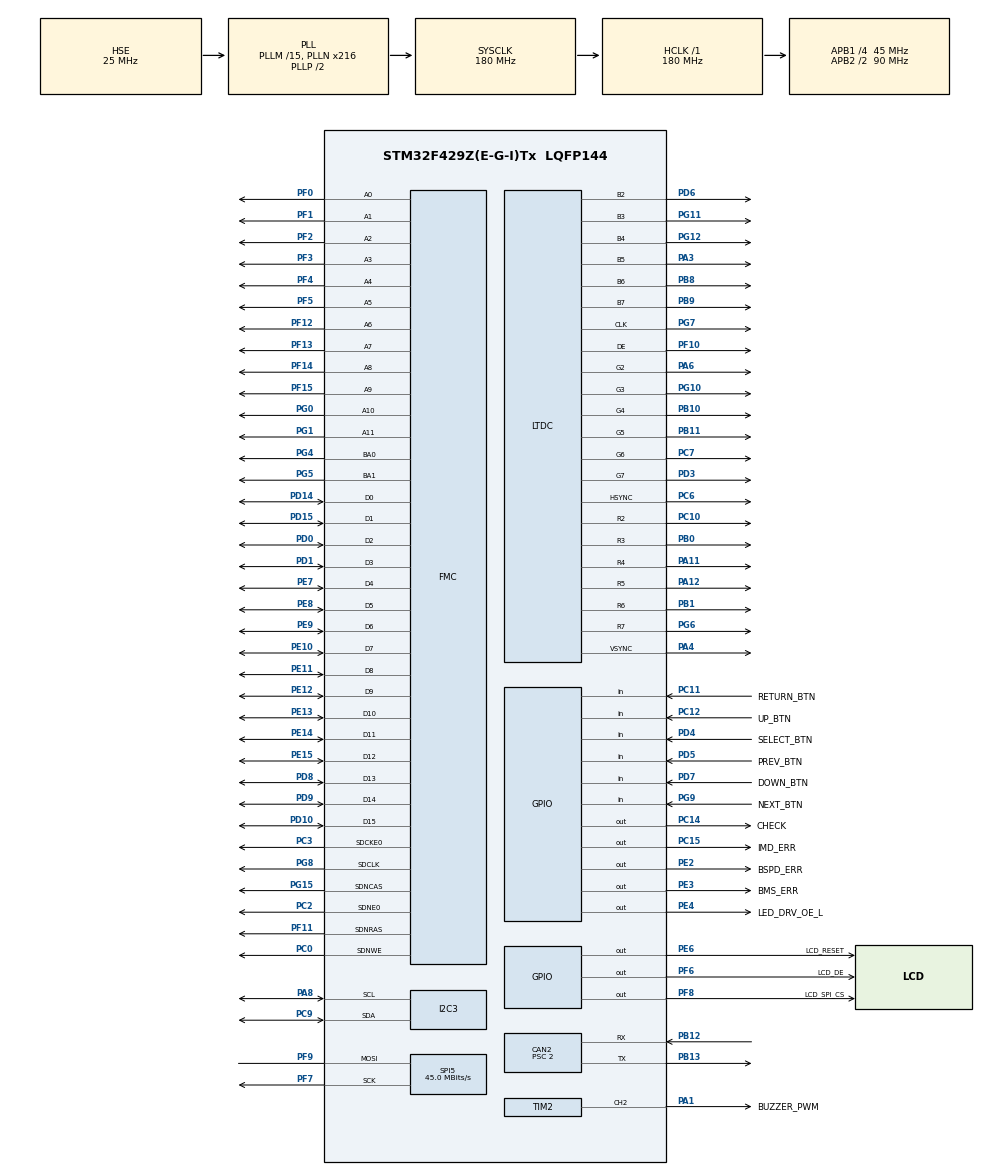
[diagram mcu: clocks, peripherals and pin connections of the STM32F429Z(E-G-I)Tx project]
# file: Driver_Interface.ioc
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CAN2.BS1=CAN_BS1_13TQ
CAN2.BS2=CAN_BS2_2TQ
CAN2.CalculateTimeBit=711
CAN2.CalculateTimeQuantum=44.44444444444444
CAN2.Prescaler=2
FREERTOS.Tasks01=defaultTask,0,128,StartDefaultTask,Default
Mcu.Family=STM32F4
Mcu.Name=STM32F429Z(E-G-I)Tx
Mcu.Package=LQFP144
NVIC.CAN2_RX0_IRQn=true\:5\:0\:false
NVIC.PriorityGroup=NVIC_PRIORITYGROUP_4
NVIC.TIM1_UP_TIM10_IRQn=true\:0\:0\:false
NVIC.TimeBase=TIM1_UP_TIM10_IRQn
NVIC.TimeBaseIP=TIM1
PA1.GPIO_Label=BUZZER_PWM
PA1.Signal=S_TIM2_CH2
PA11.Mode=RGB666
PA11.Signal=LTDC_R4
PA12.Mode=RGB666
PA12.Signal=LTDC_R5
PA13.Mode=Trace-Asynchronous_SW
PA13.Signal=SYS_JTMS-SWDIO
PA14.Mode=Trace-Asynchronous_SW
PA14.Signal=SYS_JTCK-SWCLK
PA3.Mode=RGB666
PA3.Signal=LTDC_B5
PA4.Mode=RGB666
PA4.Signal=LTDC_VSYNC
PA6.Mode=RGB666
PA6.Signal=LTDC_G2
PA8.Mode=I2C
PA8.Signal=I2C3_SCL
PB0.Mode=RGB666
PB0.Signal=LTDC_R3
PB1.Mode=RGB666
PB1.Signal=LTDC_R6
PB10.Mode=RGB666
PB10.Signal=LTDC_G4
PB11.Mode=RGB666
PB11.Signal=LTDC_G5
PB12.Mode=Slave
PB12.Signal=CAN2_RX
PB13.Mode=Slave
PB13.Signal=CAN2_TX
PB3.Mode=Trace-Asynchronous_SW
PB3.Signal=SYS_JTDO-SWO
PB8.Mode=RGB666
PB8.Signal=LTDC_B6
PB9.Mode=RGB666
PB9.Signal=LTDC_B7
PC0.Signal=FMC_SDNWE
PC10.Mode=RGB666
PC10.Signal=LTDC_R2
PC11.GPIO_Label=RETURN_BTN
PC11.Signal=GPIO_Input
PC12.GPIO_Label=UP_BTN
PC12.Signal=GPIO_Input
PC14/OSC32_IN.GPIO_Label=CHECK
PC14/OSC32_IN.Signal=GPIO_Output
PC15/OSC32_OUT.GPIO_Label=IMD_ERR
PC15/OSC32_OUT.Signal=GPIO_Output
PC2.Mode=SdramChipSelect1_1
PC2.Signal=FMC_SDNE0
PC3.Mode=SdramChipSelect1_1
PC3.Signal=FMC_SDCKE0
PC6.Mode=RGB666
PC6.Signal=LTDC_HSYNC
PC7.Mode=RGB666
PC7.Signal=LTDC_G6
PC9.Mode=I2C
PC9.Signal=I2C3_SDA
PD0.Signal=FMC_D2_DA2
PD1.Signal=FMC_D3_DA3
PD10.Signal=FMC_D15_DA15
PD14.Signal=FMC_D0_DA0
PD15.Signal=FMC_D1_DA1
PD3.Mode=RGB666
PD3.Signal=LTDC_G7
PD4.GPIO_Label=SELECT_BTN
PD4.Signal=GPIO_Input
PD5.GPIO_Label=PREV_BTN
PD5.Signal=GPIO_Input
PD6.Mode=RGB666
PD6.Signal=LTDC_B2
PD7.GPIO_Label=DOWN_BTN
PD7.Signal=GPIO_Input
PD8.Signal=FMC_D13_DA13
PD9.Signal=FMC_D14_DA14
PE10.Signal=FMC_D7_DA7
PE11.Signal=FMC_D8_DA8
PE12.Signal=FMC_D9_DA9
PE13.Signal=FMC_D10_DA10
PE14.Signal=FMC_D11_DA11
PE15.Signal=FMC_D12_DA12
PE2.GPIO_Label=BSPD_ERR
PE2.Signal=GPIO_Output
PE3.GPIO_Label=BMS_ERR
PE3.Signal=GPIO_Output
PE4.GPIO_Label=LED_DRV_OE_L
PE4.Signal=GPIO_Output
PE6.GPIO_Label=LCD_RESET
PE6.Signal=GPIO_Output
PE7.Signal=FMC_D4_DA4
PE8.Signal=FMC_D5_DA5
PE9.Signal=FMC_D6_DA6
PF0.Signal=FMC_A0
PF1.Signal=FMC_A1
PF10.Mode=RGB666
PF10.Signal=LTDC_DE
PF11.Signal=FMC_SDNRAS
PF12.Signal=FMC_A6
PF13.Signal=FMC_A7
PF14.Signal=FMC_A8
PF15.Signal=FMC_A9
PF2.Signal=FMC_A2
PF3.Signal=FMC_A3
PF4.Signal=FMC_A4
PF5.Signal=FMC_A5
PF6.GPIO_Label=LCD_DE
PF6.Signal=GPIO_Output
PF7.Mode=Simplex_Bidirectional_Master
PF7.Signal=SPI5_SCK
PF8.GPIO_Label=LCD_SPI_CS
PF8.Signal=GPIO_Output
PF9.Mode=Simplex_Bidirectional_Master
PF9.Signal=SPI5_MOSI
PG0.Signal=FMC_A10
PG1.Signal=FMC_A11
PG10.Mode=RGB666
PG10.Signal=LTDC_G3
PG11.Mode=RGB666
PG11.Signal=LTDC_B3
PG12.Mode=RGB666
PG12.Signal=LTDC_B4
PG15.Signal=FMC_SDNCAS
PG4.Signal=FMC_A14_BA0
PG5.Signal=FMC_A15_BA1
PG6.Mode=RGB666
PG6.Signal=LTDC_R7
PG7.Mode=RGB666
PG7.Signal=LTDC_CLK
PG8.Signal=FMC_SDCLK
PG9.GPIO_Label=NEXT_BTN
PG9.Signal=GPIO_Input
PH0/OSC_IN.Mode=HSE-External-Oscillator
PH0/OSC_IN.Signal=RCC_OSC_IN
PH1/OSC_OUT.Mode=HSE-External-Oscillator
PH1/OSC_OUT.Signal=RCC_OSC_OUT
ProjectManager.HeapSize=0x400
ProjectManager.StackSize=0x200
ProjectManager.TargetToolchain=SW4STM32
RCC.48MHZClocksFreq_Value=90000000
RCC.AHBFreq_Value=180000000
RCC.APB1CLKDivider=RCC_HCLK_DIV4
RCC.APB1Freq_Value=45000000
RCC.APB1TimCLKDivider=1
RCC.APB1TimFreq_Value=45000000
RCC.APB2CLKDivider=RCC_HCLK_DIV2
RCC.APB2Freq_Value=90000000
RCC.APB2TimCLKDivider=1
RCC.APB2TimFreq_Value=90000000
RCC.CortexFreq_Value=180000000
RCC.HCLKFreq_Value=180000000
RCC.HSE_VALUE=25000000
RCC.HSI_VALUE=16000000
RCC.LSE_VALUE=32768
RCC.PLLM=15
RCC.PLLN=216
RCC.PLLSAIDivR=RCC_PLLSAIDIVR_4
RCC.PLLSAIN=72
RCC.PLLSAIR=5
RCC.PLLSourceVirtual=RCC_PLLSOURCE_HSE
RCC.SYSCLKFreq_VALUE=180000000
RCC.SYSCLKSource=RCC_SYSCLKSOURCE_PLLCLK
RCC.VCOOutputFreq_Value=360000000
SH.FMC_A0.0=FMC_A0,12b-sda1
SH.FMC_A1.0=FMC_A1,12b-sda1
SH.FMC_A10.0=FMC_A10,12b-sda1
SH.FMC_A11.0=FMC_A11,12b-sda1
SH.FMC_A14_BA0.0=FMC_BA0,FourSdramBanks1
SH.FMC_A15_BA1.0=FMC_BA1,FourSdramBanks1
SH.FMC_A2.0=FMC_A2,12b-sda1
SH.FMC_A3.0=FMC_A3,12b-sda1
SH.FMC_A4.0=FMC_A4,12b-sda1
SH.FMC_A5.0=FMC_A5,12b-sda1
SH.FMC_A6.0=FMC_A6,12b-sda1
SH.FMC_A7.0=FMC_A7,12b-sda1
SH.FMC_A8.0=FMC_A8,12b-sda1
SH.FMC_A9.0=FMC_A9,12b-sda1
SH.FMC_D0_DA0.0=FMC_D0,sd-16b-d1
SH.FMC_D10_DA10.0=FMC_D10,sd-16b-d1
SH.FMC_D11_DA11.0=FMC_D11,sd-16b-d1
SH.FMC_D12_DA12.0=FMC_D12,sd-16b-d1
SH.FMC_D13_DA13.0=FMC_D13,sd-16b-d1
SH.FMC_D14_DA14.0=FMC_D14,sd-16b-d1
SH.FMC_D15_DA15.0=FMC_D15,sd-16b-d1
SH.FMC_D1_DA1.0=FMC_D1,sd-16b-d1
SH.FMC_D2_DA2.0=FMC_D2,sd-16b-d1
SH.FMC_D3_DA3.0=FMC_D3,sd-16b-d1
SH.FMC_D4_DA4.0=FMC_D4,sd-16b-d1
SH.FMC_D5_DA5.0=FMC_D5,sd-16b-d1
SH.FMC_D6_DA6.0=FMC_D6,sd-16b-d1
SH.FMC_D7_DA7.0=FMC_D7,sd-16b-d1
SH.FMC_D8_DA8.0=FMC_D8,sd-16b-d1
SH.FMC_D9_DA9.0=FMC_D9,sd-16b-d1
SH.FMC_SDCLK.0=FMC_SDCLK,12b-sda1
SH.FMC_SDNCAS.0=FMC_SDNCAS,12b-sda1
SH.FMC_SDNRAS.0=FMC_SDNRAS,12b-sda1
SH.FMC_SDNWE.0=FMC_SDNWE,12b-sda1
SH.S_TIM2_CH2.0=TIM2_CH2,PWM Generation2 CH2
SPI5.BaudRatePrescaler=SPI_BAUDRATEPRESCALER_2
SPI5.CalculateBaudRate=45.0 MBits/s
SPI5.Direction=SPI_DIRECTION_1LINE
SPI5.Mode=SPI_MODE_MASTER
TIM2.Channel-PWM\ Generation2\ CH2=TIM_CHANNEL_2
VP_DMA2D_VS_DMA2D.Mode=DMA2D_Activate
VP_FREERTOS_VS_ENABLE.Mode=Enabled
VP_SYS_VS_tim1.Mode=TIM1
board=Driver_Interface

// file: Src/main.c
/**
  ******************************************************************************
  * File Name          : main.c
  * Description        : Main program body
  ******************************************************************************
  *
  * COPYRIGHT(c) 2016 STMicroelectronics
  *
  * Redistribution and use in source and binary forms, with or without modification,
  * are permitted provided that the following conditions are met:
  *   1. Redistributions of source code must retain the above copyright notice,
  *      this list of conditions and the following disclaimer.
  *   2. Redistributions in binary form must reproduce the above copyright notice,
  *      this list of conditions and the following disclaimer in the documentation
  *      and/or other materials provided with the distribution.
  *   3. Neither the name of STMicroelectronics nor the names of its contributors
  *      may be used to endorse or promote products derived from this software
  *      without specific prior written permission.
  *
  * THIS SOFTWARE IS PROVIDED BY THE COPYRIGHT HOLDERS AND CONTRIBUTORS "AS IS"
  * AND ANY EXPRESS OR IMPLIED WARRANTIES, INCLUDING, BUT NOT LIMITED TO, THE
  * IMPLIED WARRANTIES OF MERCHANTABILITY AND FITNESS FOR A PARTICULAR PURPOSE ARE
  * DISCLAIMED. IN NO EVENT SHALL THE COPYRIGHT HOLDER OR CONTRIBUTORS BE LIABLE
  * FOR ANY DIRECT, INDIRECT, INCIDENTAL, SPECIAL, EXEMPLARY, OR CONSEQUENTIAL
  * DAMAGES (INCLUDING, BUT NOT LIMITED TO, PROCUREMENT OF SUBSTITUTE GOODS OR
  * SERVICES; LOSS OF USE, DATA, OR PROFITS; OR BUSINESS INTERRUPTION) HOWEVER
  * CAUSED AND ON ANY THEORY OF LIABILITY, WHETHER IN CONTRACT, STRICT LIABILITY,
  * OR TORT (INCLUDING NEGLIGENCE OR OTHERWISE) ARISING IN ANY WAY OUT OF THE USE
  * OF THIS SOFTWARE, EVEN IF ADVISED OF THE POSSIBILITY OF SUCH DAMAGE.
  *
  ******************************************************************************
  */
#include "stm32f4xx_hal.h"
#include "cmsis_os.h"

/* USER CODE BEGIN Includes */

#include "led.h"
#include "can.h"
#include "buttons.h"
#include "GUI.h"

#include "lcd_spi.h"
#include "ili9341.h"

/* USER CODE END Includes */

CAN_HandleTypeDef hcan2;

DMA2D_HandleTypeDef hdma2d;

I2C_HandleTypeDef hi2c3;

LTDC_HandleTypeDef hltdc;

SPI_HandleTypeDef hspi5;

TIM_HandleTypeDef htim2;

SDRAM_HandleTypeDef hsdram1;
osThreadId defaultTaskHandle;

/* USER CODE BEGIN PV */
CAN_HandleTypeDef hcan1;
/* Private variables ---------------------------------------------------------*/
osThreadId buttonTaskHandle;
osThreadId ledTaskHandle;
osThreadId canTaskHandle;
osMessageQId stateButtonQueue;
osMessageQId interfaceButtonQueue;

/* USER CODE END PV */

void SystemClock_Config(void);
static void MX_GPIO_Init(void);
static void MX_CAN2_Init(void);
static void MX_DMA2D_Init(void);
static void MX_FMC_Init(void);
static void MX_LTDC_Init(void);
static void MX_SPI5_Init(void);
static void MX_TIM2_Init(void);
static void MX_I2C3_Init(void);
void StartDefaultTask(void const * argument);

void HAL_TIM_MspPostInit(TIM_HandleTypeDef *htim);

/* USER CODE BEGIN PFP */
/* Private function prototypes -----------------------------------------------*/
/* USER CODE END PFP */

int main(void)
{

  /* MCU Configuration----------------------------------------------------------*/

  /* Reset of all peripherals, Initializes the Flash interface and the Systick. */
  HAL_Init();

  /* Configure the system clock */
  SystemClock_Config();

  /* Initialize all configured peripherals */
  MX_GPIO_Init();
  MX_CAN2_Init();
  MX_DMA2D_Init();
  MX_FMC_Init();
  MX_LTDC_Init();
  MX_SPI5_Init();
  MX_TIM2_Init();
  MX_I2C3_Init();

  /* USER CODE BEGIN 2 */
  UserInitCan2();
  HAL_GPIO_WritePin(CHECK_GPIO_Port, CHECK_Pin, GPIO_PIN_RESET);
  HAL_GPIO_WritePin(CHECK_GPIO_Port, CHECK_Pin, GPIO_PIN_SET);

//  HAL_GPIO_WritePin(BMS_ERR_GPIO_Port, BMS_ERR_Pin, GPIO_PIN_RESET);
//  HAL_GPIO_WritePin(BMS_ERR_GPIO_Port, BMS_ERR_Pin, GPIO_PIN_SET);

//  char recv_string[10] = "";
//  HAL_SDRAM_Write_8b(&hsdram1, 0, "hi", 3);
//  HAL_SDRAM_Read_8b(&hsdram1, 0, recv_string, 3);

  /* USER CODE END 2 */

  /* Create the thread(s) */
  /* definition and creation of defaultTask */
  osThreadDef(defaultTask, StartDefaultTask, osPriorityNormal, 0, 128);
  defaultTaskHandle = osThreadCreate(osThread(defaultTask), NULL);

  /* USER CODE BEGIN RTOS_THREADS */
  	  /* Button polling task. 100Hz. */
	  osThreadDef(buttonTask, vPollButtonsTask, osPriorityAboveNormal, 1, 500);
	  buttonTaskHandle = osThreadCreate(osThread(buttonTask), NULL);

	  osThreadDef(ledTask, vLedUpdateTask, osPriorityHigh, 1, 1024);
	  ledTaskHandle = osThreadCreate(osThread(ledTask), NULL);

	  osThreadDef(canTask, vCanTask, osPriorityAboveNormal, 1, 500);
	  canTaskHandle = osThreadCreate(osThread(canTask), NULL);

  /* USER CODE END RTOS_THREADS */

  /* USER CODE BEGIN RTOS_QUEUES */
	  osMessageQDef(ibutton_queue, 12, ButtonObject); // Declare a message queue
	  interfaceButtonQueue = osMessageCreate(osMessageQ(ibutton_queue), NULL);

	  osMessageQDef(sbutton_queue, 12, ButtonObject); // Declare a message queue
	  stateButtonQueue = osMessageCreate(osMessageQ(sbutton_queue), NULL);

  /* USER CODE END RTOS_QUEUES */

  /* Start scheduler */
  osKernelStart();

  /* We should never get here as control is now taken by the scheduler */

  /* Infinite loop */
  while (1)
  {

  }

}

/** System Clock Configuration
*/
void SystemClock_Config(void)
{

  RCC_OscInitTypeDef RCC_OscInitStruct;
  RCC_ClkInitTypeDef RCC_ClkInitStruct;
  RCC_PeriphCLKInitTypeDef PeriphClkInitStruct;

  __PWR_CLK_ENABLE();

  __HAL_PWR_VOLTAGESCALING_CONFIG(PWR_REGULATOR_VOLTAGE_SCALE1);

  RCC_OscInitStruct.OscillatorType = RCC_OSCILLATORTYPE_HSE;
  RCC_OscInitStruct.HSEState = RCC_HSE_ON;
  RCC_OscInitStruct.PLL.PLLState = RCC_PLL_ON;
  RCC_OscInitStruct.PLL.PLLSource = RCC_PLLSOURCE_HSE;
  RCC_OscInitStruct.PLL.PLLM = 15;
  RCC_OscInitStruct.PLL.PLLN = 216;
  RCC_OscInitStruct.PLL.PLLP = RCC_PLLP_DIV2;
  RCC_OscInitStruct.PLL.PLLQ = 4;
  HAL_RCC_OscConfig(&RCC_OscInitStruct);

  HAL_PWREx_ActivateOverDrive();

  RCC_ClkInitStruct.ClockType = RCC_CLOCKTYPE_HCLK|RCC_CLOCKTYPE_SYSCLK
                              |RCC_CLOCKTYPE_PCLK1|RCC_CLOCKTYPE_PCLK2;
  RCC_ClkInitStruct.SYSCLKSource = RCC_SYSCLKSOURCE_PLLCLK;
  RCC_ClkInitStruct.AHBCLKDivider = RCC_SYSCLK_DIV1;
  RCC_ClkInitStruct.APB1CLKDivider = RCC_HCLK_DIV4;
  RCC_ClkInitStruct.APB2CLKDivider = RCC_HCLK_DIV2;
  HAL_RCC_ClockConfig(&RCC_ClkInitStruct, FLASH_LATENCY_5);

  PeriphClkInitStruct.PeriphClockSelection = RCC_PERIPHCLK_LTDC;
  PeriphClkInitStruct.PLLSAI.PLLSAIN = 72;
  PeriphClkInitStruct.PLLSAI.PLLSAIR = 5;
  PeriphClkInitStruct.PLLSAIDivR = RCC_PLLSAIDIVR_4;
  HAL_RCCEx_PeriphCLKConfig(&PeriphClkInitStruct);

  HAL_SYSTICK_Config(HAL_RCC_GetHCLKFreq()/1000);

  HAL_SYSTICK_CLKSourceConfig(SYSTICK_CLKSOURCE_HCLK);

  /* SysTick_IRQn interrupt configuration */
  HAL_NVIC_SetPriority(SysTick_IRQn, 15, 0);
}

/* CAN2 init function */
void MX_CAN2_Init(void)
{

  hcan2.Instance = CAN2;
  hcan2.Init.Prescaler = 2;
  hcan2.Init.Mode = CAN_MODE_NORMAL;
  hcan2.Init.SJW = CAN_SJW_1TQ;
  hcan2.Init.BS1 = CAN_BS1_13TQ;
  hcan2.Init.BS2 = CAN_BS2_2TQ;
  hcan2.Init.TTCM = DISABLE;
  hcan2.Init.ABOM = DISABLE;
  hcan2.Init.AWUM = DISABLE;
  hcan2.Init.NART = DISABLE;
  hcan2.Init.RFLM = DISABLE;
  hcan2.Init.TXFP = DISABLE;
  HAL_CAN_Init(&hcan2);

}

/* DMA2D init function */
void MX_DMA2D_Init(void)
{

  hdma2d.Instance = DMA2D;
  hdma2d.Init.Mode = DMA2D_M2M;
  hdma2d.Init.ColorMode = DMA2D_ARGB8888;
  hdma2d.Init.OutputOffset = 0;
  hdma2d.LayerCfg[1].InputOffset = 0;
  hdma2d.LayerCfg[1].InputColorMode = CM_ARGB8888;
  hdma2d.LayerCfg[1].AlphaMode = DMA2D_NO_MODIF_ALPHA;
  hdma2d.LayerCfg[1].InputAlpha = 0;
  HAL_DMA2D_Init(&hdma2d);

  HAL_DMA2D_ConfigLayer(&hdma2d, 1);

}

/* I2C3 init function */
void MX_I2C3_Init(void)
{

  hi2c3.Instance = I2C3;
  hi2c3.Init.ClockSpeed = 100000;
  hi2c3.Init.DutyCycle = I2C_DUTYCYCLE_2;
  hi2c3.Init.OwnAddress1 = 0;
  hi2c3.Init.AddressingMode = I2C_ADDRESSINGMODE_7BIT;
  hi2c3.Init.DualAddressMode = I2C_DUALADDRESS_DISABLED;
  hi2c3.Init.OwnAddress2 = 0;
  hi2c3.Init.GeneralCallMode = I2C_GENERALCALL_DISABLED;
  hi2c3.Init.NoStretchMode = I2C_NOSTRETCH_DISABLED;
  HAL_I2C_Init(&hi2c3);

}

/* LTDC init function */
void MX_LTDC_Init(void)
{

  LTDC_LayerCfgTypeDef pLayerCfg;
  LTDC_LayerCfgTypeDef pLayerCfg1;

  hltdc.Instance = LTDC;
  hltdc.Init.HSPolarity = LTDC_HSPOLARITY_AL;
  hltdc.Init.VSPolarity = LTDC_VSPOLARITY_AL;
  hltdc.Init.DEPolarity = LTDC_DEPOLARITY_AL;
  hltdc.Init.PCPolarity = LTDC_PCPOLARITY_IPC;
  hltdc.Init.HorizontalSync = 7;
  hltdc.Init.VerticalSync = 3;
  hltdc.Init.AccumulatedHBP = 14;
  hltdc.Init.AccumulatedVBP = 5;
  hltdc.Init.AccumulatedActiveW = 654;
  hltdc.Init.AccumulatedActiveH = 485;
  hltdc.Init.TotalWidth = 660;
  hltdc.Init.TotalHeigh = 487;
  hltdc.Init.Backcolor.Blue = 0;
  hltdc.Init.Backcolor.Green = 0;
  hltdc.Init.Backcolor.Red = 0;
  HAL_LTDC_Init(&hltdc);

  pLayerCfg.WindowX0 = 0;
  pLayerCfg.WindowX1 = 0;
  pLayerCfg.WindowY0 = 0;
  pLayerCfg.WindowY1 = 0;
  pLayerCfg.PixelFormat = LTDC_PIXEL_FORMAT_ARGB8888;
  pLayerCfg.Alpha = 0;
  pLayerCfg.Alpha0 = 0;
  pLayerCfg.BlendingFactor1 = LTDC_BLENDING_FACTOR1_CA;
  pLayerCfg.BlendingFactor2 = LTDC_BLENDING_FACTOR2_CA;
  pLayerCfg.FBStartAdress = 0;
  pLayerCfg.ImageWidth = 0;
  pLayerCfg.ImageHeight = 0;
  pLayerCfg.Backcolor.Blue = 0;
  pLayerCfg.Backcolor.Green = 0;
  pLayerCfg.Backcolor.Red = 0;
  HAL_LTDC_ConfigLayer(&hltdc, &pLayerCfg, 0);

  pLayerCfg1.WindowX0 = 0;
  pLayerCfg1.WindowX1 = 0;
  pLayerCfg1.WindowY0 = 0;
  pLayerCfg1.WindowY1 = 0;
  pLayerCfg1.PixelFormat = LTDC_PIXEL_FORMAT_ARGB8888;
  pLayerCfg1.Alpha = 0;
  pLayerCfg1.Alpha0 = 0;
  pLayerCfg1.BlendingFactor1 = LTDC_BLENDING_FACTOR1_CA;
  pLayerCfg1.BlendingFactor2 = LTDC_BLENDING_FACTOR2_CA;
  pLayerCfg1.FBStartAdress = 0;
  pLayerCfg1.ImageWidth = 0;
  pLayerCfg1.ImageHeight = 0;
  pLayerCfg1.Backcolor.Blue = 0;
  pLayerCfg1.Backcolor.Green = 0;
  pLayerCfg1.Backcolor.Red = 0;
  HAL_LTDC_ConfigLayer(&hltdc, &pLayerCfg1, 1);

}

/* SPI5 init function */
void MX_SPI5_Init(void)
{

  hspi5.Instance = SPI5;
  hspi5.Init.Mode = SPI_MODE_MASTER;
  hspi5.Init.Direction = SPI_DIRECTION_1LINE;
  hspi5.Init.DataSize = SPI_DATASIZE_8BIT;
  hspi5.Init.CLKPolarity = SPI_POLARITY_LOW;
  hspi5.Init.CLKPhase = SPI_PHASE_1EDGE;
  hspi5.Init.NSS = SPI_NSS_SOFT;
  hspi5.Init.BaudRatePrescaler = SPI_BAUDRATEPRESCALER_2;
  hspi5.Init.FirstBit = SPI_FIRSTBIT_MSB;
  hspi5.Init.TIMode = SPI_TIMODE_DISABLED;
  hspi5.Init.CRCCalculation = SPI_CRCCALCULATION_DISABLED;
  hspi5.Init.CRCPolynomial = 10;
  HAL_SPI_Init(&hspi5);

}

/* TIM2 init function */
void MX_TIM2_Init(void)
{

  TIM_MasterConfigTypeDef sMasterConfig;
  TIM_OC_InitTypeDef sConfigOC;

  htim2.Instance = TIM2;
  htim2.Init.Prescaler = 0;
  htim2.Init.CounterMode = TIM_COUNTERMODE_UP;
  htim2.Init.Period = 0;
  htim2.Init.ClockDivision = TIM_CLOCKDIVISION_DIV1;
  HAL_TIM_PWM_Init(&htim2);

  sMasterConfig.MasterOutputTrigger = TIM_TRGO_RESET;
  sMasterConfig.MasterSlaveMode = TIM_MASTERSLAVEMODE_DISABLE;
  HAL_TIMEx_MasterConfigSynchronization(&htim2, &sMasterConfig);

  sConfigOC.OCMode = TIM_OCMODE_PWM1;
  sConfigOC.Pulse = 0;
  sConfigOC.OCPolarity = TIM_OCPOLARITY_HIGH;
  sConfigOC.OCFastMode = TIM_OCFAST_DISABLE;
  HAL_TIM_PWM_ConfigChannel(&htim2, &sConfigOC, TIM_CHANNEL_2);

  HAL_TIM_MspPostInit(&htim2);

}
/* FMC initialization function */
void MX_FMC_Init(void)
{
  FMC_SDRAM_TimingTypeDef SdramTiming;

  /** Perform the SDRAM1 memory initialization sequence
  */
  hsdram1.Instance = FMC_SDRAM_DEVICE;
  /* hsdram1.Init */
  hsdram1.Init.SDBank = FMC_SDRAM_BANK1;
  hsdram1.Init.ColumnBitsNumber = FMC_SDRAM_COLUMN_BITS_NUM_8;
  hsdram1.Init.RowBitsNumber = FMC_SDRAM_ROW_BITS_NUM_11;
  hsdram1.Init.MemoryDataWidth = FMC_SDRAM_MEM_BUS_WIDTH_16;
  hsdram1.Init.InternalBankNumber = FMC_SDRAM_INTERN_BANKS_NUM_4;
  hsdram1.Init.CASLatency = FMC_SDRAM_CAS_LATENCY_1;
  hsdram1.Init.WriteProtection = FMC_SDRAM_WRITE_PROTECTION_DISABLE;
  hsdram1.Init.SDClockPeriod = FMC_SDRAM_CLOCK_DISABLE;
  hsdram1.Init.ReadBurst = FMC_SDRAM_RBURST_DISABLE;
  hsdram1.Init.ReadPipeDelay = FMC_SDRAM_RPIPE_DELAY_0;
  /* SdramTiming */
  SdramTiming.LoadToActiveDelay = 16;
  SdramTiming.ExitSelfRefreshDelay = 16;
  SdramTiming.SelfRefreshTime = 16;
  SdramTiming.RowCycleDelay = 16;
  SdramTiming.WriteRecoveryTime = 16;
  SdramTiming.RPDelay = 16;
  SdramTiming.RCDDelay = 16;

  HAL_SDRAM_Init(&hsdram1, &SdramTiming);

}

/** Configure pins as
        * Analog
        * Input
        * Output
        * EVENT_OUT
        * EXTI
*/
void MX_GPIO_Init(void)
{

  GPIO_InitTypeDef GPIO_InitStruct;

  /* GPIO Ports Clock Enable */
  __GPIOE_CLK_ENABLE();
  __GPIOC_CLK_ENABLE();
  __GPIOF_CLK_ENABLE();
  __GPIOH_CLK_ENABLE();
  __GPIOA_CLK_ENABLE();
  __GPIOB_CLK_ENABLE();
  __GPIOG_CLK_ENABLE();
  __GPIOD_CLK_ENABLE();

  /*Configure GPIO pin Output Level */
  HAL_GPIO_WritePin(GPIOE, BSPD_ERR_Pin|BMS_ERR_Pin|LED_DRV_OE_L_Pin|LCD_RESET_Pin, GPIO_PIN_RESET);

  /*Configure GPIO pin Output Level */
  HAL_GPIO_WritePin(GPIOC, CHECK_Pin|IMD_ERR_Pin, GPIO_PIN_RESET);

  /*Configure GPIO pin Output Level */
  HAL_GPIO_WritePin(GPIOF, LCD_DE_Pin|LCD_SPI_CS_Pin, GPIO_PIN_RESET);

  /*Configure GPIO pins : BSPD_ERR_Pin BMS_ERR_Pin LED_DRV_OE_L_Pin LCD_RESET_Pin */
  GPIO_InitStruct.Pin = BSPD_ERR_Pin|BMS_ERR_Pin|LED_DRV_OE_L_Pin|LCD_RESET_Pin;
  GPIO_InitStruct.Mode = GPIO_MODE_OUTPUT_PP;
  GPIO_InitStruct.Pull = GPIO_NOPULL;
  GPIO_InitStruct.Speed = GPIO_SPEED_LOW;
  HAL_GPIO_Init(GPIOE, &GPIO_InitStruct);

  /*Configure GPIO pins : CHECK_Pin IMD_ERR_Pin */
  GPIO_InitStruct.Pin = CHECK_Pin|IMD_ERR_Pin;
  GPIO_InitStruct.Mode = GPIO_MODE_OUTPUT_PP;
  GPIO_InitStruct.Pull = GPIO_NOPULL;
  GPIO_InitStruct.Speed = GPIO_SPEED_LOW;
  HAL_GPIO_Init(GPIOC, &GPIO_InitStruct);

  /*Configure GPIO pins : LCD_DE_Pin LCD_SPI_CS_Pin */
  GPIO_InitStruct.Pin = LCD_DE_Pin|LCD_SPI_CS_Pin;
  GPIO_InitStruct.Mode = GPIO_MODE_OUTPUT_PP;
  GPIO_InitStruct.Pull = GPIO_NOPULL;
  GPIO_InitStruct.Speed = GPIO_SPEED_LOW;
  HAL_GPIO_Init(GPIOF, &GPIO_InitStruct);

  /*Configure GPIO pins : RETURN_BTN_Pin UP_BTN_Pin */
  GPIO_InitStruct.Pin = RETURN_BTN_Pin|UP_BTN_Pin;
  GPIO_InitStruct.Mode = GPIO_MODE_INPUT;
  GPIO_InitStruct.Pull = GPIO_NOPULL;
  HAL_GPIO_Init(GPIOC, &GPIO_InitStruct);

  /*Configure GPIO pins : SELECT_BTN_Pin PREV_BTN_Pin DOWN_BTN_Pin */
  GPIO_InitStruct.Pin = SELECT_BTN_Pin|PREV_BTN_Pin|DOWN_BTN_Pin;
  GPIO_InitStruct.Mode = GPIO_MODE_INPUT;
  GPIO_InitStruct.Pull = GPIO_NOPULL;
  HAL_GPIO_Init(GPIOD, &GPIO_InitStruct);

  /*Configure GPIO pin : NEXT_BTN_Pin */
  GPIO_InitStruct.Pin = NEXT_BTN_Pin;
  GPIO_InitStruct.Mode = GPIO_MODE_INPUT;
  GPIO_InitStruct.Pull = GPIO_NOPULL;
  HAL_GPIO_Init(NEXT_BTN_GPIO_Port, &GPIO_InitStruct);

}

/* StartDefaultTask function */
void StartDefaultTask(void const * argument)
{

  for(;;)
  {
    osDelay(1);
  }
}

/************************ (C) COPYRIGHT STMicroelectronics *****END OF FILE****/
